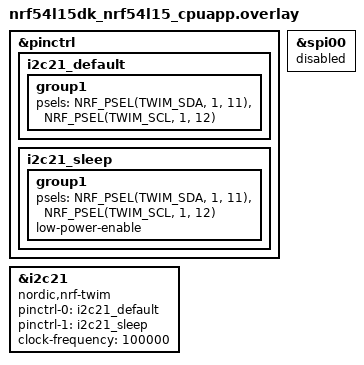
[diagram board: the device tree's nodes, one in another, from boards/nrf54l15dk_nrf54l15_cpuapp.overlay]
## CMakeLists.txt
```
cmake_minimum_required(VERSION 3.20.0)
find_package(Zephyr REQUIRED HINTS $ENV{ZEPHYR_BASE})

project(ov7670-fifo-camera)

target_sources(app PRIVATE
    src/main.c
    src/ov7670.c
    src/fifo.c
)
```

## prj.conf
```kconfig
# OV7670 FIFO Camera Demo
CONFIG_GPIO=y
CONFIG_I2C=y

# Serial console (required for any UART output on nRF54L15)
CONFIG_SERIAL=y
CONFIG_CONSOLE=y
CONFIG_UART_CONSOLE=y
CONFIG_PRINTK=y

# Logging
CONFIG_LOG=y
CONFIG_LOG_MODE_IMMEDIATE=y
CONFIG_LOG_BACKEND_UART=y

CONFIG_MAIN_STACK_SIZE=4096
```

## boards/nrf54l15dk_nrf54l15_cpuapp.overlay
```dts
/*
 * Device tree overlay for OV7670 + FIFO camera on nRF54L15 DK
 *
 * I2C (SCCB): SIOD = P1.11, SIOC = P1.12  (i2c21 / TWIM21 — Arduino I2C header)
 * Data bus D0-D7 = P2.00-P2.07  (read as low byte of port 2)
 * VSYNC = P2.08,  WRST = P2.10,  RCK = P2.09
 * XCLK: provided by 12 MHz oscillator on the camera PCB
 *
 * P1.04-P1.07 — UART20 console          DO NOT USE
 * P2.07 — LED2 (D7: FIFO drives OK, LED flickers with data)
 * P2.09 — LED0 (RCK: LED blinks during frame readout — capture indicator)
 *
 * NOTE: P1.11 and P1.12 are the Arduino-compatible I2C header pins on PCA10156.
 * P1.00/P1.01 are NOT wired to any header on this board.
 */

&pinctrl {
	i2c21_default: i2c21_default {
		group1 {
			psels = <NRF_PSEL(TWIM_SDA, 1, 11)>,
				<NRF_PSEL(TWIM_SCL, 1, 12)>;
			/* External 4.7 kΩ pull-ups present — no internal bias needed */
		};
	};

	i2c21_sleep: i2c21_sleep {
		group1 {
			psels = <NRF_PSEL(TWIM_SDA, 1, 11)>,
				<NRF_PSEL(TWIM_SCL, 1, 12)>;
			low-power-enable;
		};
	};
};

&i2c21 {
	compatible = "nordic,nrf-twim";
	status = "okay";
	pinctrl-0 = <&i2c21_default>;
	pinctrl-1 = <&i2c21_sleep>;
	pinctrl-names = "default", "sleep";
	clock-frequency = <100000>;
};

/*
 * Disable the on-board SPI flash (MX25R64) and SPI00 peripheral.
 * They claim P2.00 (reset), P2.01 (SCK), P2.02 (MOSI), P2.04 (MISO),
 * P2.05 (CS) — which collide with our FIFO data bus D0-D7 on P2.00-P2.07.
 *
 * NOTE: Even with SPI00 disabled, the flash chip is physically soldered
 * to these traces. If bus contention causes problems, the data bus
 * may need to be moved to different pins.
 */
&spi00 {
	status = "disabled";
};
```

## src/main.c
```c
/*
 * OV7670 + FIFO Camera Demo — nRF54L15 DK (Zephyr)
 *
 * Captures QQVGA (160×120) RGB565 frames once per second.
 * Set DUMP_FRAME_UART to 1 to hex-dump each frame over UART.
 * See README.md for hardware wiring and Board Configurator requirements.
 * See src/fifo.c for the full pin mapping.
 */

#include <zephyr/kernel.h>
#include <zephyr/logging/log.h>

#include "ov7670.h"
#include "fifo.h"

LOG_MODULE_REGISTER(app, LOG_LEVEL_INF);

/* Set to 1 to hex-dump every captured frame over UART */
#define DUMP_FRAME_UART  1

static uint8_t frame_buf[IMG_SIZE] __aligned(4);

int main(void)
{
	printk("\n*** OV7670 FIFO Camera Demo ***\n");

	if (ov7670_init() != 0) {
		return -EIO;
	}

	if (fifo_init() != 0) {
		return -EIO;
	}

	k_msleep(300);   /* auto-exposure settle */

	LOG_INF("Ready — capturing QQVGA %dx%d RGB565 (%u bytes/frame)",
		IMG_W, IMG_H, (unsigned)IMG_SIZE);

	for (uint32_t n = 1; ; n++) {
		fifo_capture(frame_buf, IMG_SIZE);
		LOG_INF("Frame #%u captured (%u bytes @ %p)",
			n, (unsigned)IMG_SIZE, (void *)frame_buf);

#if DUMP_FRAME_UART
		/* Hex dump — pipe the console to a file on the host. */
		printk("\r\n---FRAME_START---\r\n");
		for (size_t i = 0; i < IMG_SIZE; i++) {
			printk("%02x", frame_buf[i]);
			if ((i & 31) == 31) {
				printk("\r\n");
			}
		}
		printk("\r\n---FRAME_END---\r\n");
#endif

		k_msleep(1000);
	}

	return 0;
}
```
